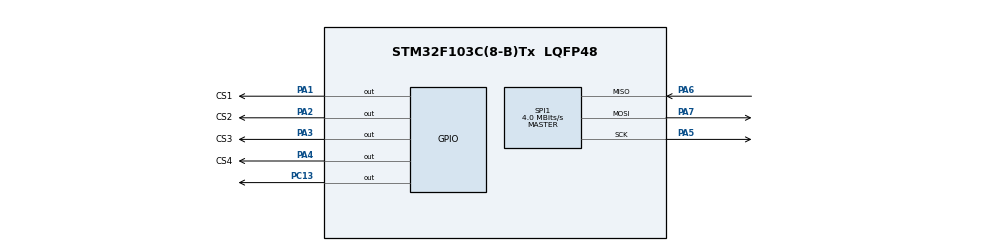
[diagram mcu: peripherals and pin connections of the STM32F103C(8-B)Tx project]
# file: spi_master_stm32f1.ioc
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Mcu.Family=STM32F1
Mcu.Name=STM32F103C(8-B)Tx
Mcu.Package=LQFP48
NVIC.PriorityGroup=NVIC_PRIORITYGROUP_4
NVIC.SPI1_IRQn=true\:0\:0\:false\:false\:true\:true\:true\:true
PA1.GPIO_Label=CS1
PA1.GPIO_PuPd=GPIO_PULLUP
PA1.GPIO_Speed=GPIO_SPEED_FREQ_MEDIUM
PA1.PinState=GPIO_PIN_SET
PA1.Signal=GPIO_Output
PA13.Mode=Serial_Wire
PA13.Signal=SYS_JTMS-SWDIO
PA14.Mode=Serial_Wire
PA14.Signal=SYS_JTCK-SWCLK
PA2.GPIO_Label=CS2
PA2.GPIO_PuPd=GPIO_PULLUP
PA2.GPIO_Speed=GPIO_SPEED_FREQ_MEDIUM
PA2.PinState=GPIO_PIN_SET
PA2.Signal=GPIO_Output
PA3.GPIO_Label=CS3
PA3.GPIO_PuPd=GPIO_PULLUP
PA3.GPIO_Speed=GPIO_SPEED_FREQ_MEDIUM
PA3.PinState=GPIO_PIN_SET
PA3.Signal=GPIO_Output
PA4.GPIO_Label=CS4
PA4.GPIO_PuPd=GPIO_PULLUP
PA4.GPIO_Speed=GPIO_SPEED_FREQ_MEDIUM
PA4.PinState=GPIO_PIN_SET
PA4.Signal=GPIO_Output
PA5.GPIO_Speed=GPIO_SPEED_FREQ_HIGH
PA5.Mode=Full_Duplex_Master
PA5.Signal=SPI1_SCK
PA6.Mode=Full_Duplex_Master
PA6.Signal=SPI1_MISO
PA7.GPIO_Speed=GPIO_SPEED_FREQ_HIGH
PA7.Mode=Full_Duplex_Master
PA7.Signal=SPI1_MOSI
PC13-TAMPER-RTC.Signal=GPIO_Output
PD0-OSC_IN.Mode=HSE-External-Oscillator
PD0-OSC_IN.Signal=RCC_OSC_IN
PD1-OSC_OUT.Mode=HSE-External-Oscillator
PD1-OSC_OUT.Signal=RCC_OSC_OUT
ProjectManager.HeapSize=0x200
ProjectManager.StackSize=0x400
ProjectManager.TargetToolchain=STM32CubeIDE
RCC.AHBFreq_Value=8000000
RCC.APB1Freq_Value=8000000
RCC.APB1TimFreq_Value=8000000
RCC.APB2Freq_Value=8000000
RCC.APB2TimFreq_Value=8000000
RCC.HCLKFreq_Value=8000000
RCC.PLLMUL=RCC_PLL_MUL4
RCC.SYSCLKFreq_VALUE=8000000
RCC.USBFreq_Value=16000000
SPI1.CalculateBaudRate=4.0 MBits/s
SPI1.Direction=SPI_DIRECTION_2LINES
SPI1.Mode=SPI_MODE_MASTER
SPI1.VirtualType=VM_MASTER
board=custom

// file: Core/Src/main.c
/* USER CODE BEGIN Header */
/**
  ******************************************************************************
  * @file           : main.c
  * @brief          : Main program body
  ******************************************************************************
  * @attention
  *
  * Copyright (c) 2024 STMicroelectronics.
  * All rights reserved.
  *
  * This software is licensed under terms that can be found in the LICENSE file
  * in the root directory of this software component.
  * If no LICENSE file comes with this software, it is provided AS-IS.
  *
  ******************************************************************************
  */
/* USER CODE END Header */
#include "main.h"

/* USER CODE BEGIN Includes */
#include "spi.h"
/* USER CODE END Includes */

void SystemClock_Config(void);
static void MX_GPIO_Init(void);
static void MX_SPI1_Init(void);

int main(void)
{

  /* MCU Configuration--------------------------------------------------------*/

  /* Reset of all peripherals, Initializes the Flash interface and the Systick. */
  LL_APB2_GRP1_EnableClock(LL_APB2_GRP1_PERIPH_AFIO);
  LL_APB1_GRP1_EnableClock(LL_APB1_GRP1_PERIPH_PWR);

  /* System interrupt init*/
  NVIC_SetPriorityGrouping(NVIC_PRIORITYGROUP_4);

  /* SysTick_IRQn interrupt configuration */
  NVIC_SetPriority(SysTick_IRQn, NVIC_EncodePriority(NVIC_GetPriorityGrouping(),15, 0));

  /** NOJTAG: JTAG-DP Disabled and SW-DP Enabled
  */
  LL_GPIO_AF_Remap_SWJ_NOJTAG();

  /* Configure the system clock */
  SystemClock_Config();

  /* Initialize all configured peripherals */
  MX_GPIO_Init();
  MX_SPI1_Init();
  /* USER CODE BEGIN 2 */
//uint8_t id_manufacter[4];
uint8_t tx_data[4]={0x01,0x13,0x14,0x15};
  /* USER CODE END 2 */

  /* Infinite loop */
  while (1)
  {

    /* USER CODE BEGIN 3 */
//	  reset_device();
//	  read_id_manufacter(id_manufacter);
//	  write_data(0x30, tx_data, 1);
//	   Kéo CS xuống mức 0 để bắt đầu giao tiếp
	  LL_GPIO_ResetOutputPin(CS3_GPIO_Port, CS3_Pin);
	  // Bật tính năng ghi bằng lệnh Write Enable (0x06)
	  spi_transmit(&tx_data[0], 1, 1000);
	  // Kéo CS lên mức 1 để hoàn thành lệnh
	  LL_GPIO_SetOutputPin(CS3_GPIO_Port, CS3_Pin);
	  tx_data[0]++;
	  LL_GPIO_TogglePin(GPIOC, LL_GPIO_PIN_13);
	  LL_mDelay(1000);
//	  LL_mDelay(5);
  }
  /* USER CODE END 3 */
}

void SystemClock_Config(void)
{
  LL_FLASH_SetLatency(LL_FLASH_LATENCY_0);
  while(LL_FLASH_GetLatency()!= LL_FLASH_LATENCY_0)
  {
  }
  LL_RCC_HSI_SetCalibTrimming(16);
  LL_RCC_HSI_Enable();

   /* Wait till HSI is ready */
  while(LL_RCC_HSI_IsReady() != 1)
  {

  }
  LL_RCC_SetAHBPrescaler(LL_RCC_SYSCLK_DIV_1);
  LL_RCC_SetAPB1Prescaler(LL_RCC_APB1_DIV_1);
  LL_RCC_SetAPB2Prescaler(LL_RCC_APB2_DIV_1);
  LL_RCC_SetSysClkSource(LL_RCC_SYS_CLKSOURCE_HSI);

   /* Wait till System clock is ready */
  while(LL_RCC_GetSysClkSource() != LL_RCC_SYS_CLKSOURCE_STATUS_HSI)
  {

  }
  LL_Init1msTick(8000000);
  LL_SetSystemCoreClock(8000000);
}

static void MX_SPI1_Init(void)
{

  LL_SPI_InitTypeDef SPI_InitStruct = {0};

  LL_GPIO_InitTypeDef GPIO_InitStruct = {0};

  /* Peripheral clock enable */
  LL_APB2_GRP1_EnableClock(LL_APB2_GRP1_PERIPH_SPI1);

  LL_APB2_GRP1_EnableClock(LL_APB2_GRP1_PERIPH_GPIOA);
  /**SPI1 GPIO Configuration
  PA5   ------> SPI1_SCK
  PA6   ------> SPI1_MISO
  PA7   ------> SPI1_MOSI
  */
  GPIO_InitStruct.Pin = LL_GPIO_PIN_5|LL_GPIO_PIN_7;
  GPIO_InitStruct.Mode = LL_GPIO_MODE_ALTERNATE;
  GPIO_InitStruct.Speed = LL_GPIO_SPEED_FREQ_HIGH;
  GPIO_InitStruct.OutputType = LL_GPIO_OUTPUT_PUSHPULL;
  LL_GPIO_Init(GPIOA, &GPIO_InitStruct);

  GPIO_InitStruct.Pin = LL_GPIO_PIN_6;
  GPIO_InitStruct.Mode = LL_GPIO_MODE_FLOATING;
  LL_GPIO_Init(GPIOA, &GPIO_InitStruct);

  /* SPI1 interrupt Init */
  NVIC_SetPriority(SPI1_IRQn, NVIC_EncodePriority(NVIC_GetPriorityGrouping(),0, 0));
  NVIC_EnableIRQ(SPI1_IRQn);

  /* SPI1 parameter configuration*/
  SPI_InitStruct.TransferDirection = LL_SPI_FULL_DUPLEX;
  SPI_InitStruct.Mode = LL_SPI_MODE_MASTER;
  SPI_InitStruct.DataWidth = LL_SPI_DATAWIDTH_8BIT;
  SPI_InitStruct.ClockPolarity = LL_SPI_POLARITY_LOW;
  SPI_InitStruct.ClockPhase = LL_SPI_PHASE_1EDGE;
  SPI_InitStruct.NSS = LL_SPI_NSS_SOFT;
  SPI_InitStruct.BaudRate = LL_SPI_BAUDRATEPRESCALER_DIV2;
  SPI_InitStruct.BitOrder = LL_SPI_MSB_FIRST;
  SPI_InitStruct.CRCCalculation = LL_SPI_CRCCALCULATION_DISABLE;
  SPI_InitStruct.CRCPoly = 10;
  LL_SPI_Init(SPI1, &SPI_InitStruct);
  /* USER CODE BEGIN SPI1_Init 2 */
  LL_SPI_Enable(SPI1);
  /* USER CODE END SPI1_Init 2 */

}

static void MX_GPIO_Init(void)
{
  LL_GPIO_InitTypeDef GPIO_InitStruct = {0};

  /* GPIO Ports Clock Enable */
  LL_APB2_GRP1_EnableClock(LL_APB2_GRP1_PERIPH_GPIOC);
  LL_APB2_GRP1_EnableClock(LL_APB2_GRP1_PERIPH_GPIOD);
  LL_APB2_GRP1_EnableClock(LL_APB2_GRP1_PERIPH_GPIOA);

  /**/
  LL_GPIO_ResetOutputPin(GPIOC, LL_GPIO_PIN_13);

  /**/
  LL_GPIO_SetOutputPin(GPIOA, CS1_Pin|CS2_Pin|CS3_Pin|CS4_Pin);

  /**/
  GPIO_InitStruct.Pin = LL_GPIO_PIN_13;
  GPIO_InitStruct.Mode = LL_GPIO_MODE_OUTPUT;
  GPIO_InitStruct.Speed = LL_GPIO_SPEED_FREQ_LOW;
  GPIO_InitStruct.OutputType = LL_GPIO_OUTPUT_PUSHPULL;
  LL_GPIO_Init(GPIOC, &GPIO_InitStruct);

  /**/
  GPIO_InitStruct.Pin = CS1_Pin|CS2_Pin|CS3_Pin|CS4_Pin;
  GPIO_InitStruct.Mode = LL_GPIO_MODE_OUTPUT;
  GPIO_InitStruct.Speed = LL_GPIO_SPEED_FREQ_MEDIUM;
  GPIO_InitStruct.OutputType = LL_GPIO_OUTPUT_PUSHPULL;
  GPIO_InitStruct.Pull = LL_GPIO_PULL_UP;
  LL_GPIO_Init(GPIOA, &GPIO_InitStruct);

}

void Error_Handler(void)
{
  __disable_irq();
  while (1)
  {
  }
}
